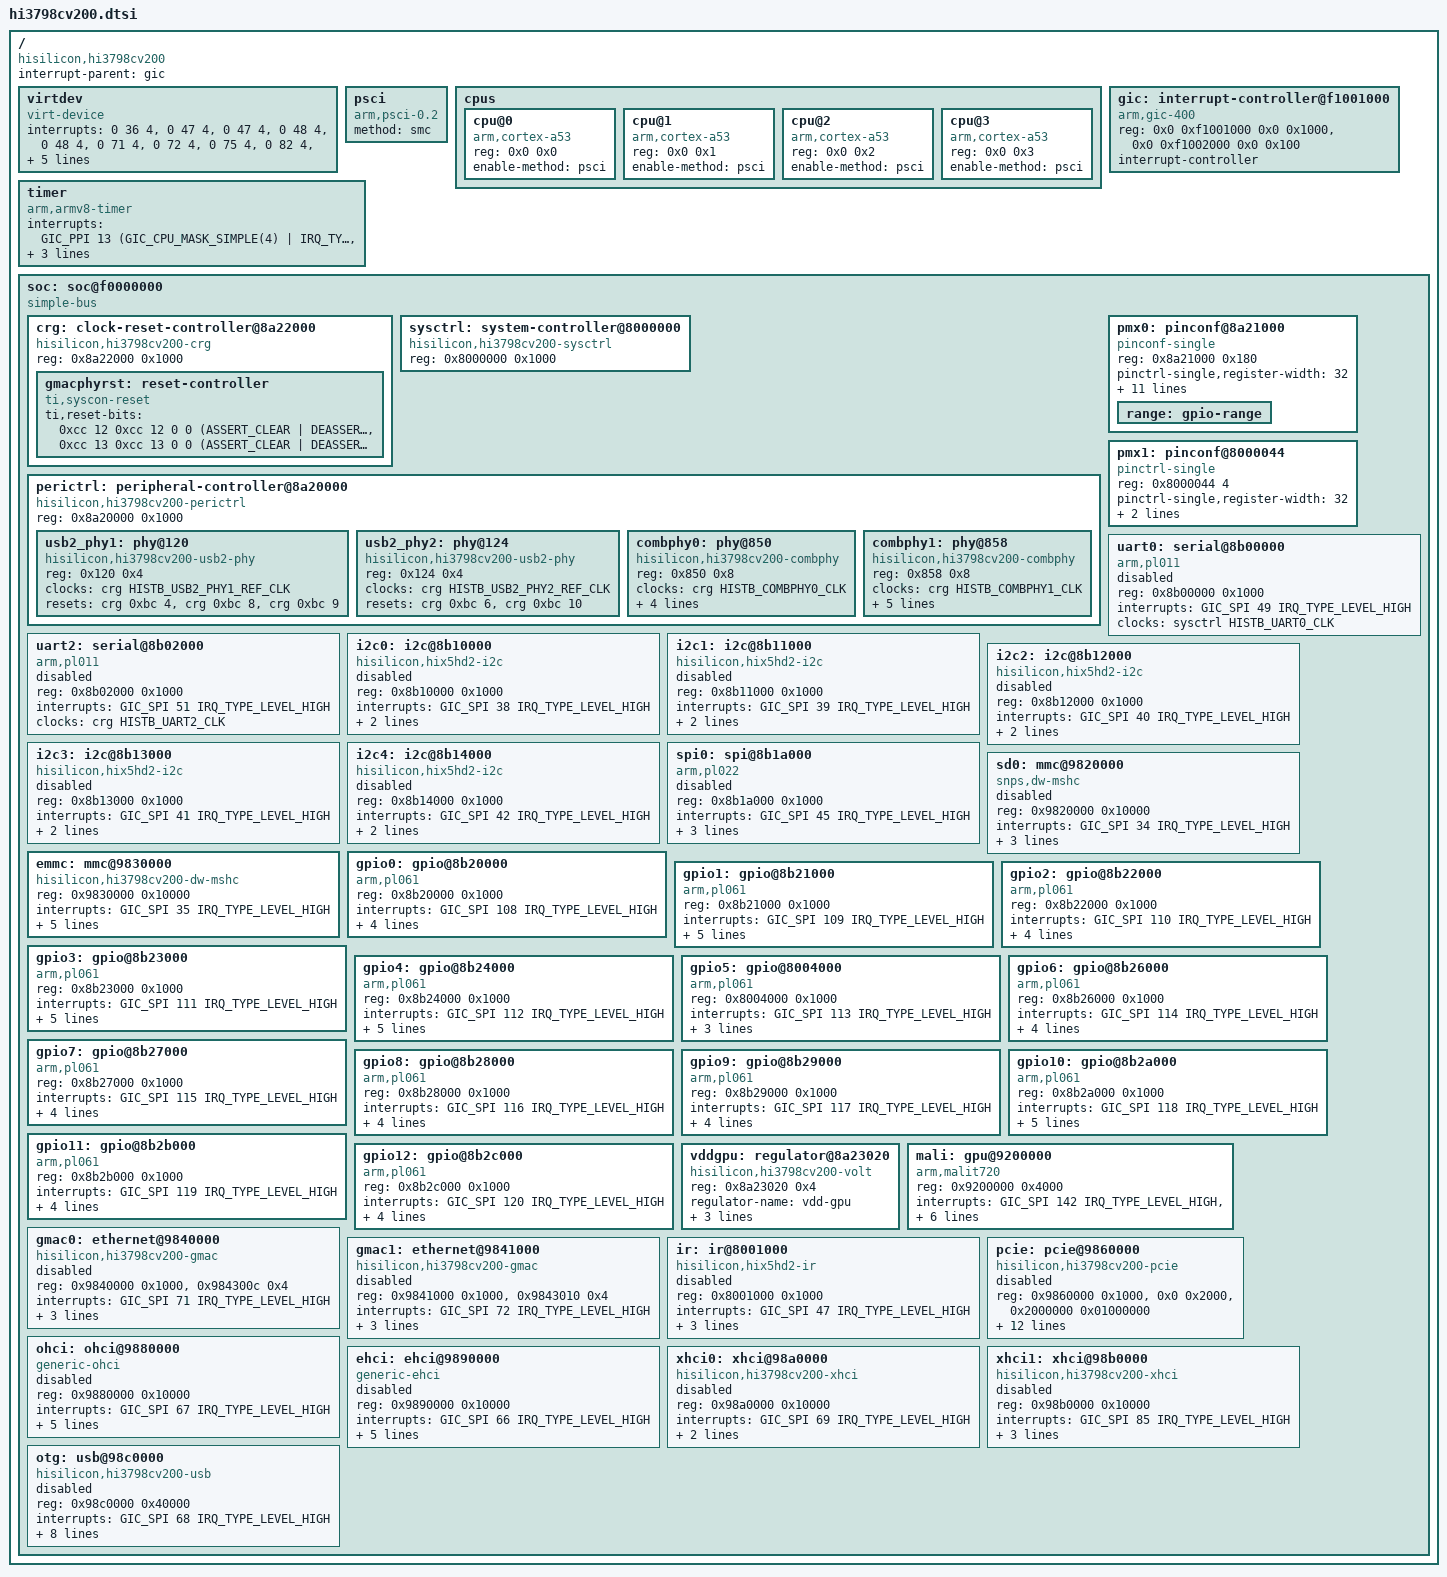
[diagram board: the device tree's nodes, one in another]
/*
 * DTS File for HiSilicon Hi3798cv200 SoC.
 *
 * Copyright (c) 2016-2017 HiSilicon Technologies Co., Ltd.
 *
 * Released under the GPLv2 only.
 * SPDX-License-Identifier: GPL-2.0
 */

#include <dt-bindings/clock/histb-clock.h>
#include <dt-bindings/gpio/gpio.h>
#include <dt-bindings/interrupt-controller/arm-gic.h>
#include <dt-bindings/phy/phy.h>
#include <dt-bindings/reset/ti-syscon.h>

/ {
	compatible = "hisilicon,hi3798cv200";
	interrupt-parent = <&gic>;
	#address-cells = <2>;
	#size-cells = <2>;

	virtdev {
		compatible = "virt-device";
		interrupts = <0 36 4>,  /* "sci0"          */
			     <0 47 4>,  /* "ir_std"        */
			     <0 47 4>,  /* "ir_s2"         */
			     <0 48 4>,  /* "keyled_ct1642" */
			     <0 48 4>,  /* "keyled_std"    */
			     <0 71 4>,  /* "gsf0"          */
			     <0 72 4>,  /* "gsf1"          */
			     <0 75 4>,  /* "multicipher"   */
			     <0 82 4>,  /* "dmx"           */
			     <0 84 4>,  /* "aiao"          */
			     <0 88 4>,  /* "hdmi"          */
			     <0 90 4>,  /* "vdp"           */
			     <0 91 4>,  /* "tde"           */
			     <0 92 4>,  /* "gfx2d"         */
			     <0 93 4>,  /* "vpss0"         */
			     <0 95 4>,  /* "vdec_vdh"      */
			     <0 96 4>,  /* "png"           */
			     <0 97 4>,  /* "jpeg"          */
			     <0 101 4>, /* "venc"          */
			     <0 102 4>, /* "jpge"          */
			     <0 104 4>, /* "vdec_scd"      */
			     <0 105 4>, /* "vdec_vdh_safe" */
			     <0 106 4>, /* "vdec_scd_safe" */
			     <0 126 4>, /* "cipher"        */
			     <0 141 4>, /* "gpu_mmu"       */
			     <0 142 4>, /* "gpu_job"       */
			     <0 143 4>, /* "gpu"           */
			     <0 146 4>, /* "SecInvokeirq"  */
			     <0 147 4>, /* "hdmi_cec"      */
			     <0 148 4>, /* "mmu_vdh_safe"  */
			     <0 149 4>, /* "mmu_vdh"       */
			     <0 150 4>; /* "pastc"         */
		interrupt-names = /* 36  */ "sci0",
				  /* 47  */ "ir_std",
				  /* 47  */ "ir_s2",
				  /* 48  */ "keyled_ct1642",
				  /* 48  */ "keyled_std",
				  /* 71  */ "gsf0",
				  /* 72  */ "gsf1",
				  /* 75  */ "multicipher",
				  /* 82  */ "dmx",
				  /* 84  */ "aiao",
				  /* 88  */ "hdmi",
				  /* 90  */ "vdp",
				  /* 91  */ "tde",
				  /* 92  */ "gfx2d",
				  /* 93  */ "vpss0",
				  /* 95  */ "vdec_vdh",
				  /* 96  */ "png",
				  /* 97  */ "jpeg",
				  /* 101 */ "venc",
				  /* 102 */ "jpge",
				  /* 104 */ "vdec_scd",
				  /* 105 */ "vdec_vdh_safe",
				  /* 106 */ "vdec_scd_safe",
				  /* 126 */ "cipher",
				  /* 141 */ "gpu_mmu",
				  /* 142 */ "gpu_job",
				  /* 143 */ "gpu",
				  /* 146 */ "SecInvokeirq",
				  /* 147 */ "hdmi_cec",
				  /* 148 */ "mmu_vdh_safe",
				  /* 149 */ "mmu_vdh",
				  /* 150 */ "pastc";
	};

	psci {
		compatible = "arm,psci-0.2";
		method = "smc";
	};

	cpus {
		#address-cells = <2>;
		#size-cells = <0>;

		cpu@0 {
			compatible = "arm,cortex-a53";
			device_type = "cpu";
			reg = <0x0 0x0>;
			enable-method = "psci";
		};

		cpu@1 {
			compatible = "arm,cortex-a53";
			device_type = "cpu";
			reg = <0x0 0x1>;
			enable-method = "psci";
		};

		cpu@2 {
			compatible = "arm,cortex-a53";
			device_type = "cpu";
			reg = <0x0 0x2>;
			enable-method = "psci";
		};

		cpu@3 {
			compatible = "arm,cortex-a53";
			device_type = "cpu";
			reg = <0x0 0x3>;
			enable-method = "psci";
		};
	};

	gic: interrupt-controller@f1001000 {
		compatible = "arm,gic-400";
		reg = <0x0 0xf1001000 0x0 0x1000>,  /* GICD */
		      <0x0 0xf1002000 0x0 0x100>;   /* GICC */
		#address-cells = <0>;
		#interrupt-cells = <3>;
		interrupt-controller;
	};

	timer {
		compatible = "arm,armv8-timer";
		interrupts = <GIC_PPI 13 (GIC_CPU_MASK_SIMPLE(4) |
			      IRQ_TYPE_LEVEL_LOW)>,
			     <GIC_PPI 14 (GIC_CPU_MASK_SIMPLE(4) |
			      IRQ_TYPE_LEVEL_LOW)>,
			     <GIC_PPI 11 (GIC_CPU_MASK_SIMPLE(4) |
			      IRQ_TYPE_LEVEL_LOW)>,
			     <GIC_PPI 10 (GIC_CPU_MASK_SIMPLE(4) |
			      IRQ_TYPE_LEVEL_LOW)>;
	};

	soc: soc@f0000000 {
		compatible = "simple-bus";
		#address-cells = <1>;
		#size-cells = <1>;
		ranges = <0x0 0x0 0xf0000000 0x10000000>;

		crg: clock-reset-controller@8a22000 {
			compatible = "hisilicon,hi3798cv200-crg", "syscon", "simple-mfd";
			reg = <0x8a22000 0x1000>;
			#clock-cells = <1>;
			#reset-cells = <2>;

			gmacphyrst: reset-controller {
				compatible = "ti,syscon-reset";
				#reset-cells = <1>;
				ti,reset-bits =
					<0xcc 12 0xcc 12 0 0 (ASSERT_CLEAR |
					 DEASSERT_SET|STATUS_NONE)>,
					<0xcc 13 0xcc 13 0 0 (ASSERT_CLEAR |
					 DEASSERT_SET|STATUS_NONE)>;
			};
		};

		sysctrl: system-controller@8000000 {
			compatible = "hisilicon,hi3798cv200-sysctrl", "syscon";
			reg = <0x8000000 0x1000>;
			#clock-cells = <1>;
			#reset-cells = <2>;
		};

		perictrl: peripheral-controller@8a20000 {
			compatible = "hisilicon,hi3798cv200-perictrl", "syscon",
				     "simple-mfd";
			reg = <0x8a20000 0x1000>;
			#address-cells = <1>;
			#size-cells = <1>;
			ranges = <0x0 0x8a20000 0x1000>;

			usb2_phy1: phy@120 {
				compatible = "hisilicon,hi3798cv200-usb2-phy";
				reg = <0x120 0x4>;
				#phy-cells = <1>;
				clocks = <&crg HISTB_USB2_PHY1_REF_CLK>;
				resets = <&crg 0xbc 4>,
					 <&crg 0xbc 8>,
					 <&crg 0xbc 9>;
				reset-names = "power_on", "utmi0", "utmi1";
			};

			usb2_phy2: phy@124 {
				compatible = "hisilicon,hi3798cv200-usb2-phy";
				reg = <0x124 0x4>;
				#phy-cells = <1>;
				clocks = <&crg HISTB_USB2_PHY2_REF_CLK>;
				resets = <&crg 0xbc 6>,
					 <&crg 0xbc 10>;
				reset-names = "power_on", "utmi0";
			};

			combphy0: phy@850 {
				compatible = "hisilicon,hi3798cv200-combphy";
				reg = <0x850 0x8>;
				#phy-cells = <1>;
				clocks = <&crg HISTB_COMBPHY0_CLK>;
				resets = <&crg 0x188 4>;
				assigned-clocks = <&crg HISTB_COMBPHY0_CLK>;
				assigned-clock-rates = <100000000>;
				hisilicon,fixed-mode = <PHY_TYPE_USB3>;
			};

			combphy1: phy@858 {
				compatible = "hisilicon,hi3798cv200-combphy";
				reg = <0x858 0x8>;
				#phy-cells = <1>;
				clocks = <&crg HISTB_COMBPHY1_CLK>;
				resets = <&crg 0x188 12>;
				assigned-clocks = <&crg HISTB_COMBPHY1_CLK>;
				assigned-clock-rates = <100000000>;
				hisilicon,mode-select-bits = <0x0008 11 (0x3 << 11)>;
			};
		};

		pmx0: pinconf@8a21000 {
			compatible = "pinconf-single";
			reg = <0x8a21000 0x180>;
			pinctrl-single,register-width = <32>;
			pinctrl-single,function-mask = <7>;
			pinctrl-single,gpio-range = <
				&range 0  8 2  /* GPIO 0 */
				&range 8  1 0  /* GPIO 1 */
				&range 9  4 2
				&range 13 1 0
				&range 14 1 1
				&range 15 1 0
				&range 16 5 0  /* GPIO 2 */
				&range 21 3 1
				&range 24 4 1  /* GPIO 3 */
				&range 28 2 2
				&range 86 1 1
				&range 87 1 0
				&range 30 4 2  /* GPIO 4 */
				&range 34 3 0
				&range 37 1 2
				&range 38 3 2  /* GPIO 6 */
				&range 41 5 0
				&range 46 8 1  /* GPIO 7 */
				&range 54 8 1  /* GPIO 8 */
				&range 64 7 1  /* GPIO 9 */
				&range 71 1 0
				&range 72 6 1  /* GPIO 10 */
				&range 78 1 0
				&range 79 1 1
				&range 80 6 1  /* GPIO 11 */
				&range 70 2 1
				&range 88 8 0  /* GPIO 12 */
			>;

			range: gpio-range {
				#pinctrl-single,gpio-range-cells = <3>;
			};
		};

		pmx1: pinconf@8000044 {
			compatible = "pinctrl-single";
			reg = <0x8000044 4>;
			pinctrl-single,register-width = <32>;
			pinctrl-single,function-mask = <1>;
			pinctrl-single,bit-per-mux;
		};

		uart0: serial@8b00000 {
			compatible = "arm,pl011", "arm,primecell";
			reg = <0x8b00000 0x1000>;
			interrupts = <GIC_SPI 49 IRQ_TYPE_LEVEL_HIGH>;
			clocks = <&sysctrl HISTB_UART0_CLK>;
			clock-names = "apb_pclk";
			status = "disabled";
		};

		uart2: serial@8b02000 {
			compatible = "arm,pl011", "arm,primecell";
			reg = <0x8b02000 0x1000>;
			interrupts = <GIC_SPI 51 IRQ_TYPE_LEVEL_HIGH>;
			clocks = <&crg HISTB_UART2_CLK>;
			clock-names = "apb_pclk";
			status = "disabled";
		};

		i2c0: i2c@8b10000 {
			compatible = "hisilicon,hix5hd2-i2c";
			reg = <0x8b10000 0x1000>;
			#address-cells = <1>;
			#size-cells = <0>;
			interrupts = <GIC_SPI 38 IRQ_TYPE_LEVEL_HIGH>;
			clock-frequency = <400000>;
			clocks = <&crg HISTB_I2C0_CLK>;
			status = "disabled";
		};

		i2c1: i2c@8b11000 {
			compatible = "hisilicon,hix5hd2-i2c";
			reg = <0x8b11000 0x1000>;
			#address-cells = <1>;
			#size-cells = <0>;
			interrupts = <GIC_SPI 39 IRQ_TYPE_LEVEL_HIGH>;
			clock-frequency = <400000>;
			clocks = <&crg HISTB_I2C1_CLK>;
			status = "disabled";
		};

		i2c2: i2c@8b12000 {
			compatible = "hisilicon,hix5hd2-i2c";
			reg = <0x8b12000 0x1000>;
			#address-cells = <1>;
			#size-cells = <0>;
			interrupts = <GIC_SPI 40 IRQ_TYPE_LEVEL_HIGH>;
			clock-frequency = <400000>;
			clocks = <&crg HISTB_I2C2_CLK>;
			status = "disabled";
		};

		i2c3: i2c@8b13000 {
			compatible = "hisilicon,hix5hd2-i2c";
			reg = <0x8b13000 0x1000>;
			#address-cells = <1>;
			#size-cells = <0>;
			interrupts = <GIC_SPI 41 IRQ_TYPE_LEVEL_HIGH>;
			clock-frequency = <400000>;
			clocks = <&crg HISTB_I2C3_CLK>;
			status = "disabled";
		};

		i2c4: i2c@8b14000 {
			compatible = "hisilicon,hix5hd2-i2c";
			reg = <0x8b14000 0x1000>;
			#address-cells = <1>;
			#size-cells = <0>;
			interrupts = <GIC_SPI 42 IRQ_TYPE_LEVEL_HIGH>;
			clock-frequency = <400000>;
			clocks = <&crg HISTB_I2C4_CLK>;
			status = "disabled";
		};

		spi0: spi@8b1a000 {
			compatible = "arm,pl022", "arm,primecell";
			reg = <0x8b1a000 0x1000>;
			interrupts = <GIC_SPI 45 IRQ_TYPE_LEVEL_HIGH>;
			num-cs = <1>;
			cs-gpios = <&gpio7 1 0>;
			clocks = <&crg HISTB_SPI0_CLK>;
			clock-names = "apb_pclk";
			#address-cells = <1>;
			#size-cells = <0>;
			status = "disabled";
		};

		sd0: mmc@9820000 {
			compatible = "snps,dw-mshc";
			reg = <0x9820000 0x10000>;
			interrupts = <GIC_SPI 34 IRQ_TYPE_LEVEL_HIGH>;
			clocks = <&crg HISTB_SDIO0_CIU_CLK>,
				 <&crg HISTB_SDIO0_BIU_CLK>;
			clock-names = "ciu", "biu";
			resets = <&crg 0x9c 4>;
			reset-names = "reset";
			status = "disabled";
		};

		emmc: mmc@9830000 {
			compatible = "hisilicon,hi3798cv200-dw-mshc";
			reg = <0x9830000 0x10000>;
			interrupts = <GIC_SPI 35 IRQ_TYPE_LEVEL_HIGH>;
			clocks = <&crg HISTB_MMC_CIU_CLK>,
				 <&crg HISTB_MMC_BIU_CLK>,
				 <&crg HISTB_MMC_SAMPLE_CLK>,
				 <&crg HISTB_MMC_DRV_CLK>;
			clock-names = "ciu", "biu", "ciu-sample", "ciu-drive";
			resets = <&crg 0xa0 4>;
			reset-names = "reset";
		};

		gpio0: gpio@8b20000 {
			compatible = "arm,pl061", "arm,primecell";
			reg = <0x8b20000 0x1000>;
			interrupts = <GIC_SPI 108 IRQ_TYPE_LEVEL_HIGH>;
			gpio-controller;
			#gpio-cells = <2>;
			interrupt-controller;
			#interrupt-cells = <2>;
			gpio-ranges = <&pmx0 0 0 8>;
			clocks = <&crg HISTB_APB_CLK>;
			clock-names = "apb_pclk";
		};

		gpio1: gpio@8b21000 {
			compatible = "arm,pl061", "arm,primecell";
			reg = <0x8b21000 0x1000>;
			interrupts = <GIC_SPI 109 IRQ_TYPE_LEVEL_HIGH>;
			gpio-controller;
			#gpio-cells = <2>;
			interrupt-controller;
			#interrupt-cells = <2>;
			gpio-ranges = <
				&pmx0 0 8 1
				&pmx0 1 9 4
				&pmx0 5 13 1
				&pmx0 6 14 1
				&pmx0 7 15 1
			>;
			clocks = <&crg HISTB_APB_CLK>;
			clock-names = "apb_pclk";
		};

		gpio2: gpio@8b22000 {
			compatible = "arm,pl061", "arm,primecell";
			reg = <0x8b22000 0x1000>;
			interrupts = <GIC_SPI 110 IRQ_TYPE_LEVEL_HIGH>;
			gpio-controller;
			#gpio-cells = <2>;
			interrupt-controller;
			#interrupt-cells = <2>;
			gpio-ranges = <&pmx0 0 16 5 &pmx0 5 21 3>;
			clocks = <&crg HISTB_APB_CLK>;
			clock-names = "apb_pclk";
		};

		gpio3: gpio@8b23000 {
			compatible = "arm,pl061", "arm,primecell";
			reg = <0x8b23000 0x1000>;
			interrupts = <GIC_SPI 111 IRQ_TYPE_LEVEL_HIGH>;
			gpio-controller;
			#gpio-cells = <2>;
			interrupt-controller;
			#interrupt-cells = <2>;
			gpio-ranges = <
				&pmx0 0 24 4
				&pmx0 4 28 2
				&pmx0 6 86 1
				&pmx0 7 87 1
			>;
			clocks = <&crg HISTB_APB_CLK>;
			clock-names = "apb_pclk";
		};

		gpio4: gpio@8b24000 {
			compatible = "arm,pl061", "arm,primecell";
			reg = <0x8b24000 0x1000>;
			interrupts = <GIC_SPI 112 IRQ_TYPE_LEVEL_HIGH>;
			gpio-controller;
			#gpio-cells = <2>;
			interrupt-controller;
			#interrupt-cells = <2>;
			gpio-ranges = <&pmx0 0 30 4 &pmx0 4 34 3 &pmx0 7 37 1>;
			clocks = <&crg HISTB_APB_CLK>;
			clock-names = "apb_pclk";
		};

		gpio5: gpio@8004000 {
			compatible = "arm,pl061", "arm,primecell";
			reg = <0x8004000 0x1000>;
			interrupts = <GIC_SPI 113 IRQ_TYPE_LEVEL_HIGH>;
			gpio-controller;
			#gpio-cells = <2>;
			interrupt-controller;
			#interrupt-cells = <2>;
			clocks = <&crg HISTB_APB_CLK>;
			clock-names = "apb_pclk";
		};

		gpio6: gpio@8b26000 {
			compatible = "arm,pl061", "arm,primecell";
			reg = <0x8b26000 0x1000>;
			interrupts = <GIC_SPI 114 IRQ_TYPE_LEVEL_HIGH>;
			gpio-controller;
			#gpio-cells = <2>;
			interrupt-controller;
			#interrupt-cells = <2>;
			gpio-ranges = <&pmx0 0 38 3 &pmx0 0 41 5>;
			clocks = <&crg HISTB_APB_CLK>;
			clock-names = "apb_pclk";
		};

		gpio7: gpio@8b27000 {
			compatible = "arm,pl061", "arm,primecell";
			reg = <0x8b27000 0x1000>;
			interrupts = <GIC_SPI 115 IRQ_TYPE_LEVEL_HIGH>;
			gpio-controller;
			#gpio-cells = <2>;
			interrupt-controller;
			#interrupt-cells = <2>;
			gpio-ranges = <&pmx0 0 46 8>;
			clocks = <&crg HISTB_APB_CLK>;
			clock-names = "apb_pclk";
		};

		gpio8: gpio@8b28000 {
			compatible = "arm,pl061", "arm,primecell";
			reg = <0x8b28000 0x1000>;
			interrupts = <GIC_SPI 116 IRQ_TYPE_LEVEL_HIGH>;
			gpio-controller;
			#gpio-cells = <2>;
			interrupt-controller;
			#interrupt-cells = <2>;
			gpio-ranges = <&pmx0 0 54 8>;
			clocks = <&crg HISTB_APB_CLK>;
			clock-names = "apb_pclk";
		};

		gpio9: gpio@8b29000 {
			compatible = "arm,pl061", "arm,primecell";
			reg = <0x8b29000 0x1000>;
			interrupts = <GIC_SPI 117 IRQ_TYPE_LEVEL_HIGH>;
			gpio-controller;
			#gpio-cells = <2>;
			interrupt-controller;
			#interrupt-cells = <2>;
			gpio-ranges = <&pmx0 0 64 7 &pmx0 7 71 1>;
			clocks = <&crg HISTB_APB_CLK>;
			clock-names = "apb_pclk";
		};

		gpio10: gpio@8b2a000 {
			compatible = "arm,pl061", "arm,primecell";
			reg = <0x8b2a000 0x1000>;
			interrupts = <GIC_SPI 118 IRQ_TYPE_LEVEL_HIGH>;
			gpio-controller;
			#gpio-cells = <2>;
			interrupt-controller;
			#interrupt-cells = <2>;
			gpio-ranges = <&pmx0 0 72 6 &pmx0 6 78 1 &pmx0 7 79 1>;
			clocks = <&crg HISTB_APB_CLK>;
			clock-names = "apb_pclk";
		};

		gpio11: gpio@8b2b000 {
			compatible = "arm,pl061", "arm,primecell";
			reg = <0x8b2b000 0x1000>;
			interrupts = <GIC_SPI 119 IRQ_TYPE_LEVEL_HIGH>;
			gpio-controller;
			#gpio-cells = <2>;
			interrupt-controller;
			#interrupt-cells = <2>;
			gpio-ranges = <&pmx0 0 80 6 &pmx0 6 70 2>;
			clocks = <&crg HISTB_APB_CLK>;
			clock-names = "apb_pclk";
		};

		gpio12: gpio@8b2c000 {
			compatible = "arm,pl061", "arm,primecell";
			reg = <0x8b2c000 0x1000>;
			interrupts = <GIC_SPI 120 IRQ_TYPE_LEVEL_HIGH>;
			gpio-controller;
			#gpio-cells = <2>;
			interrupt-controller;
			#interrupt-cells = <2>;
			gpio-ranges = <&pmx0 0 88 8>;
			clocks = <&crg HISTB_APB_CLK>;
			clock-names = "apb_pclk";
		};

		vddgpu: regulator@8a23020 {
			compatible = "hisilicon,hi3798cv200-volt";
			reg = <0x8a23020 0x4>;
			reg-names = "base-address";
			regulator-name = "vdd-gpu";
			regulator-min-microvolt = <650000>;
			regulator-max-microvolt = <1150000>;
			regulator-always-on;
		};

		mali: gpu@9200000 {
			compatible = "arm,malit720", "arm,mali", "arm,mali-midgard";
			reg = <0x9200000 0x4000>;
			interrupts = <GIC_SPI 142 IRQ_TYPE_LEVEL_HIGH>,
				     <GIC_SPI 141 IRQ_TYPE_LEVEL_HIGH>,
				     <GIC_SPI 143 IRQ_TYPE_LEVEL_HIGH>;
			interrupt-names = "JOB", "MMU", "GPU";
			clocks = <&crg HISTB_GPU_CLK>;
			clock-names = "clk_mali";
			mali-supply = <&vddgpu>;
			operating-points = <
				200000 880000
				300000 880000
				400000 880000
				500000 880000
				600000 920000
				675000 980000
			>;
		};

		gmac0: ethernet@9840000 {
			compatible = "hisilicon,hi3798cv200-gmac", "hisilicon,hisi-gmac-v2";
			reg = <0x9840000 0x1000>,
			      <0x984300c 0x4>;
			interrupts = <GIC_SPI 71 IRQ_TYPE_LEVEL_HIGH>;
			clocks = <&crg HISTB_ETH0_MAC_CLK>,
				 <&crg HISTB_ETH0_MACIF_CLK>;
			clock-names = "mac_core", "mac_ifc";
			resets = <&crg 0xcc 8>,
				 <&crg 0xcc 10>,
				 <&gmacphyrst 0>;
			reset-names = "mac_core", "mac_ifc", "phy";
			status = "disabled";
		};

		gmac1: ethernet@9841000 {
			compatible = "hisilicon,hi3798cv200-gmac", "hisilicon,hisi-gmac-v2";
			reg = <0x9841000 0x1000>,
			      <0x9843010 0x4>;
			interrupts = <GIC_SPI 72 IRQ_TYPE_LEVEL_HIGH>;
			clocks = <&crg HISTB_ETH1_MAC_CLK>,
				 <&crg HISTB_ETH1_MACIF_CLK>;
			clock-names = "mac_core", "mac_ifc";
			resets = <&crg 0xcc 9>,
				 <&crg 0xcc 11>,
				 <&gmacphyrst 1>;
			reset-names = "mac_core", "mac_ifc", "phy";
			status = "disabled";
		};

		ir: ir@8001000 {
			compatible = "hisilicon,hix5hd2-ir";
			reg = <0x8001000 0x1000>;
			interrupts = <GIC_SPI 47 IRQ_TYPE_LEVEL_HIGH>;
			clocks = <&sysctrl HISTB_IR_CLK>;
			hisilicon,power-syscon = <&sysctrl>;
			linux,rc-map-name = "rc-hisi-poplar";
			status = "disabled";
		};

		pcie: pcie@9860000 {
			compatible = "hisilicon,hi3798cv200-pcie";
			reg = <0x9860000 0x1000>,
			      <0x0 0x2000>,
			      <0x2000000 0x01000000>;
			reg-names = "control", "rc-dbi", "config";
			#address-cells = <3>;
			#size-cells = <2>;
			device_type = "pci";
			bus-range = <0 15>;
			num-lanes = <1>;
			ranges = <0x81000000 0x0 0x00000000 0x4f00000 0x0 0x100000
				  0x82000000 0x0 0x3000000 0x3000000 0x0 0x01f00000>;
			interrupts = <GIC_SPI 128 IRQ_TYPE_LEVEL_HIGH>;
			interrupt-names = "msi";
			#interrupt-cells = <1>;
			interrupt-map-mask = <0 0 0 0>;
			interrupt-map = <0 0 0 0 &gic 0 131 IRQ_TYPE_LEVEL_HIGH>;
			clocks = <&crg HISTB_PCIE_AUX_CLK>,
				 <&crg HISTB_PCIE_PIPE_CLK>,
				 <&crg HISTB_PCIE_SYS_CLK>,
				 <&crg HISTB_PCIE_BUS_CLK>;
			clock-names = "aux", "pipe", "sys", "bus";
			resets = <&crg 0x18c 6>, <&crg 0x18c 5>, <&crg 0x18c 4>;
			reset-names = "soft", "sys", "bus";
			phys = <&combphy1 PHY_TYPE_PCIE>;
			phy-names = "phy";
			status = "disabled";
		};

		ohci: ohci@9880000 {
			compatible = "generic-ohci";
			reg = <0x9880000 0x10000>;
			interrupts = <GIC_SPI 67 IRQ_TYPE_LEVEL_HIGH>;
			clocks = <&crg HISTB_USB2_BUS_CLK>,
				 <&crg HISTB_USB2_12M_CLK>,
				 <&crg HISTB_USB2_48M_CLK>;
			clock-names = "bus", "clk12", "clk48";
			resets = <&crg 0xb8 12>;
			reset-names = "bus";
			phys = <&usb2_phy1 0>;
			phy-names = "usb";
			status = "disabled";
		};

		ehci: ehci@9890000 {
			compatible = "generic-ehci";
			reg = <0x9890000 0x10000>;
			interrupts = <GIC_SPI 66 IRQ_TYPE_LEVEL_HIGH>;
			clocks = <&crg HISTB_USB2_BUS_CLK>,
				 <&crg HISTB_USB2_PHY_CLK>,
				 <&crg HISTB_USB2_UTMI_CLK>;
			clock-names = "bus", "phy", "utmi";
			resets = <&crg 0xb8 12>,
				 <&crg 0xb8 16>,
				 <&crg 0xb8 13>;
			reset-names = "bus", "phy", "utmi";
			phys = <&usb2_phy1 0>;
			phy-names = "usb";
			status = "disabled";
		};

		xhci0: xhci@98a0000 {
			compatible = "hisilicon,hi3798cv200-xhci";
			reg = <0x98a0000 0x10000>;
			interrupts = <GIC_SPI 69 IRQ_TYPE_LEVEL_HIGH>;
			clocks = <&crg HISTB_USB3_CLK>;
			phys = <&usb2_phy1 1>, <&combphy0 PHY_TYPE_USB3>;
			phy-names = "usb", "combo";
			status = "disabled";
		};

		xhci1: xhci@98b0000 {
			compatible = "hisilicon,hi3798cv200-xhci";
			reg = <0x98b0000 0x10000>;
			interrupts = <GIC_SPI 85 IRQ_TYPE_LEVEL_HIGH>;
			clocks = <&crg HISTB_USB3_CLK1>;
			phys = <&usb2_phy2 0>;
			phy-names = "usb";
			hisilicon,peripheral-syscon = <&perictrl 0x13c>;
			status = "disabled";
		};

		otg: usb@98c0000 {
			compatible = "hisilicon,hi3798cv200-usb";
			reg = <0x98c0000 0x40000>;
			interrupts = <GIC_SPI 68 IRQ_TYPE_LEVEL_HIGH>;
			clocks = <&crg HISTB_USB2_OTG_UTMI_CLK>;
			clock-names = "otg";
			resets = <&crg 0xb8 17>;
			reset-names = "dwc2";
			phys = <&usb2_phy1 0>;
			phy-names = "usb2-phy";
			dr_mode = "peripheral";
			g-use-dma;
			g-rx-fifo-size = <271>;
			g-np-tx-fifo-size = <64>;
			g-tx-fifo-size = <128 128>;
			status = "disabled";
		};
	};
};
